# SAM9X75D1GN2 device description
Architecture: ARM926EJ-S; Family: SAM9; Series: SAM9X7
Registers are 32-bit, read-write, reset 0x0 unless marked. A register's access mark holds for its fields unless they carry their own. Offsets are from the block's base; [hi:lo] are bit positions; lines under a group give offsets from that group; {n}, {i} and the like mark numbered series.

## CSI2DC — CSI-2 Demultiplexer Controller
Instances: CSI2DC 0xF805C000
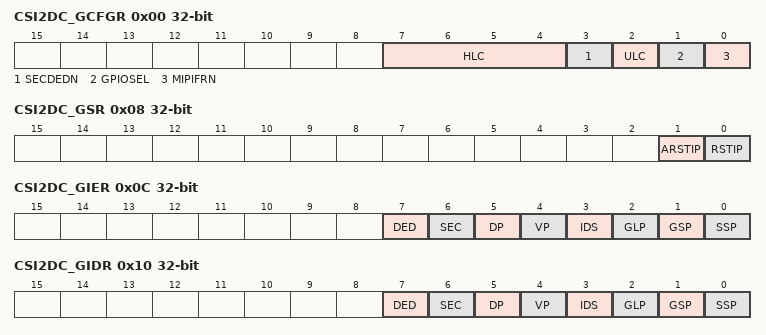
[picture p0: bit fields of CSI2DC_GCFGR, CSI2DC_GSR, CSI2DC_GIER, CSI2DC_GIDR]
0x00 CSI2DC_GCFGR — Global Configuration Register
  [7:4] HLC — CSI2DC Output Waveform Inter-line Minimum Delay
  [3] SECDEDN — Single Error Correction Double Error Detection Enable
    0=Packet header error correction is activated; 1=Packet header error correction is disabled
  [2] ULC — Use Optional Line Packet Delimiter
    0=Line packets are not used to define the line boundary; 1=Line Start and Line End optional packets are used to activate and deactivate the line
  [1] GPIOSEL — GPIO Parallel Interface Selection
    0=The MIPI CSI-2 serial interface is activated; 1=The GPIO parallel interface is selected and internally routed to the Image Signal Processor
  [0] MIPIFRN — MIPI Interface Free Running Clock
    0=The sensor MIPI clock is free-running; 1=The sensor MIPI clock is gated
0x04 CSI2DC_GCTLR wo reset not defined — Global Control Register
  [0] SWRST — Software Reset
    0=No effect; 1=Starts a software reset operation
0x08 CSI2DC_GSR ro — Global Status Register
  [1] ARSTIP — Asynchronous Reset in Progress
    0=No reset in progress for the asynchronous domain; 1=Asynchronous domain is being reset
  [0] RSTIP — Reset in Progress
    0=No reset in progress for the synchronous domain; 1=Synchronous domain is being reset
0x0C CSI2DC_GIER wo reset not defined (atomic set of CSI2DC_GIMR) — Global Interrupt Enable Register
  [7] DED — Packet Header Double Bit Error Detected Enable
  [6] SEC — Packet Header Single Bit Error Corrected Enable
  [5] DP — Data Pipe Interrupt Enable
  [4] VP — Video Pipe Interrupt Enable
  [3] IDS — Image Data Packet Snoop Controller Interrupt Enable
  [2] GLP — Generic Long Packet Interrupt Enable
  [1] GSP — Generic Short Packet Interrupt Enable
  [0] SSP — Synchronization Short Packet Interrupt Enable
0x10 CSI2DC_GIDR wo reset not defined (atomic clear of CSI2DC_GIMR) — Global Interrupt Disable Register
  [7] DED — Double Bit Error Detected Interrupt Disable
  [6] SEC — Single Bit Error Corrected Interrupt Disable
  [5] DP — Data Pipe Interrupt Disable
  [4] VP — Video Pipe Interrupt Disable
  [3] IDS — Image Data Packet Snoop Controller Interrupt Disable
  [2] GLP — Generic Long Packet Interrupt Disable
  [1] GSP — Generic Short Packet Interrupt Disable
  [0] SSP — Synchronization Short Packet Interrupt Disable
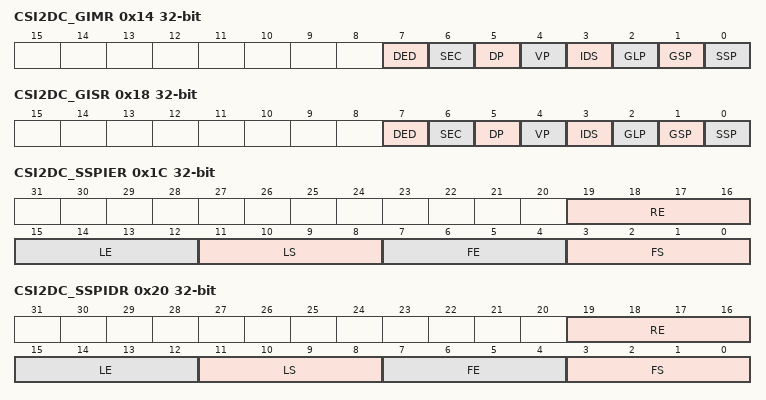
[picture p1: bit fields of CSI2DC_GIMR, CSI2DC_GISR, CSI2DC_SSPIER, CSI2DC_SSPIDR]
0x14 CSI2DC_GIMR ro — Global Interrupt Mask Register
  [7] DED — Double Error Detected Interrupt Disable Interrupt Mask
  [6] SEC — Single Error Corrected Interrupt Disable Interrupt Mask
  [5] DP — Data Pipe Interrupt Disable Interrupt Mask
  [4] VP — Video Pipe Interrupt Disable Interrupt Mask
  [3] IDS — Image Data Packet Snoop Controller Interrupt Mask
  [2] GLP — Generic Long Packet Interrupt Mask
  [1] GSP — Generic Short Packet Interrupt Mask
  [0] SSP — Synchronization Short Packet Interrupt Mask
0x18 CSI2DC_GISR ro — Global Interrupt Status Register
  [7] DED — Double Bit Error Detected Interrupt Status
    0=No double bit error detected is pending; 1=A double bit error has been detected in the packet header. This bit is reset after the register read operation.
  [6] SEC — Single Bit Error Corrected Interrupt Status
    0=No Single Bit Error Corrected interrupt is pending; 1=A single bit error has been detected and corrected in the packet header. This bit is reset after the register read operation.
  [5] DP — Data Pipe Interrupt Status
    0=Either the interrupt source is masked at the DP level or no interrupt is pending for DP; 1=A Data Pipe interrupt is pending
  [4] VP — Video Pipe Interrupt Status
    0=Either the interrupt source is masked at the VP level or no interrupt is pending for VP; 1=A Video Pipe interrupt is pending
  [3] IDS — Image Data Packet Snoop Controller Interrupt Status
    0=Either the interrupt source is masked at the IDS level or no interrupt is pending for IDS; 1=A new Image Data packet interrupt is pending
  [2] GLP — Generic Long Packet Interrupt Status
    0=Either the interrupt source is masked at the GLP level or no interrupt is pending for GLP; 1=A Generic Long packet interrupt is pending
  [1] GSP — Generic Short Packet Interrupt Status
    0=Either the interrupt source is masked at the GSP level or no interrupt is pending for GSP; 1=A Generic Short packet interrupt is pending
  [0] SSP — Synchronization Short Packet Interrupt Status
    0=Either the interrupt source is masked at the SSP level or no interrupt is pending for SSP; 1=A Synchronization Short packet interrupt is pending
0x1C CSI2DC_SSPIER wo reset not defined (atomic set of CSI2DC_SSPIMR) — SSP Interrupt Enable Register
  [19:16] RE — Reserved Short Packet Interrupt Enable
    0=No effect; 1=Setting a bit at position i in the RE field will set the interrupt mask bit for virtual channel i, and this virtual channel can generate an interrupt when a Reserved Short packet is detected
  [15:12] LE — Line End Interrupt Enable
    0=No effect; 1=Setting a bit at position i in the LE field will set the interrupt mask bit for virtual channel i, and this virtual channel can generate an interrupt when a Line End is detected. Line Synchronization packets are optional.
  [11:8] LS — Line Start Interrupt Enable
    0=No effect; 1=Setting a bit at position i in the LS field will set the interrupt mask bit for virtual channel i, and this virtual channel can generate an interrupt when a Line Start is detected. Line Synchronization packets are optional.
  [7:4] FE — Frame End Interrupt Enable
    0=No effect; 1=Setting a bit at position i in the FE field will set the interrupt mask bit for virtual channel i, and this virtual channel can generate an interrupt when a Frame End is detected
  [3:0] FS — Frame Start Interrupt Enable
    0=No effect; 1=Setting a bit at position i in the FS field will set the interrupt mask bit for virtual channel i, and this virtual channel can generate an interrupt when a Frame Start is detected
0x20 CSI2DC_SSPIDR wo reset not defined (atomic clear of CSI2DC_SSPIMR) — SSP Interrupt Disable Register
  [19:16] RE — Reserved Short Packet Interrupt Disable
  [15:12] LE — Line End Interrupt Disable
  [11:8] LS — Line Start Interrupt Disable
  [7:4] FE — Frame End Interrupt Disable
  [3:0] FS — Frame Start Interrupt Disable
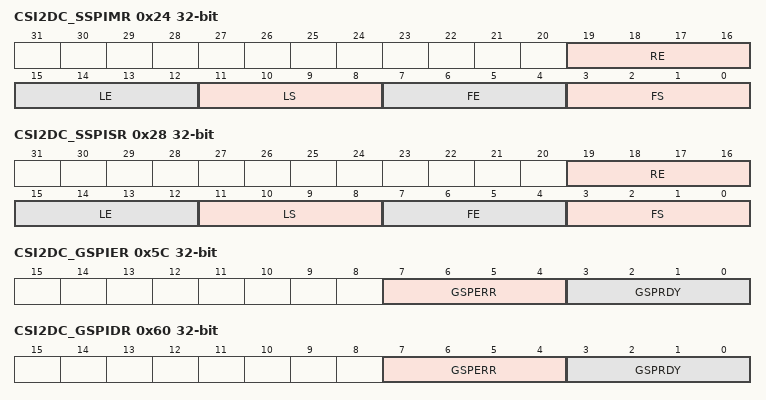
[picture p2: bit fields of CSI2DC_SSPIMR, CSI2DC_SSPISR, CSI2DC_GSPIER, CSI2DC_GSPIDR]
0x24 CSI2DC_SSPIMR ro — SSP Interrupt Mask Register
  [19:16] RE — Reserved Short Packet Interrupt Mask
    0=A bit cleared at position i in the field RE indicates that the Reserved packet interrupt is masked for virtual channel i; 1=A bit set at position i in field RE indicates that Reserved packet interrupt is activated for virtual channel i
  [15:12] LE — Line End Interrupt Mask
    0=A bit cleared at position i in the field LE indicates that the Line End interrupt is masked for virtual channel i; 1=A bit set at position i in field LE indicates that Line End interrupt is activated for virtual channel i
  [11:8] LS — Line Start Interrupt Mask
    0=A bit cleared at position i in the field LS indicates that the Line Start interrupt is masked for virtual channel i; 1=A bit set at position i in field LS indicates that Line Start interrupt is activated for virtual channel i
  [7:4] FE — Frame End Interrupt Mask
    0=A bit cleared at position i in the field FE indicates that the Frame End interrupt is masked for virtual channel i; 1=A bit set at position i in field FE indicates that Frame End interrupt is activated for virtual channel i
  [3:0] FS — Frame Start Interrupt Mask
    0=A bit cleared at position i in the field FS indicates that the Frame Start interrupt is masked for virtual channel i; 1=A bit set at position i in field FS indicates that Frame Start interrupt is activated for virtual channel i
0x28 CSI2DC_SSPISR ro — SSP Interrupt Status Register
  [19:16] RE — Reserved Short Packet Interrupt Status
    0=A bit cleared at position i in the field RE indicates that no Reserved Short packet interrupt is pending for virtual channel i; 1=A bit set at position i in the field RE indicates that no Reserved Short packet interrupt is pending for virtual channel i. This bit is reset after the register read operation.
  [15:12] LE — Line End Interrupt Status
    0=A bit cleared at position i in the field LE indicates that no Line End interrupt is pending for virtual channel i; 1=A bit set at position i in the field LE indicates that a Line End interrupt is pending for virtual channel i. This bit is reset after the register read operation.
  [11:8] LS — Line Start Interrupt Status
    0=A bit cleared at position i in the field LS indicates that no Line Start interrupt is pending for virtual channel i; 1=A bit set at position i in the field LS indicates that a Line Start interrupt is pending for virtual channel i. This bit is reset after the register read operation.
  [7:4] FE — Frame End Interrupt Status
    0=A bit cleared at position i in the field FE indicates that no Frame End interrupt is pending for virtual channel i; 1=A bit set at position i in the field FE indicates that a Frame End interrupt is pending for virtual channel i. This bit is reset after the register read operation..
  [3:0] FS — Frame Start Interrupt Status
    0=A bit cleared at position i in the field FS indicates that no Frame Start interrupt is pending for virtual channel i; 1=A bit set at position i in the field FS indicates that a Frame Start interrupt is pending for virtual channel i. This bit is reset after the register read operation.
{0x2C+4i} CSI2DC_FNVC{i}R ro (i=0..3) — Frame Number VC0 Register
  [15:0] FN — Frame Number for Virtual Channel 0
{0x3C+4i} CSI2DC_LNVC{i}R ro (i=0..3) — Line Number VC0 Register
  [15:0] LN — Line Number for Virtual Channel 0
0x5C CSI2DC_GSPIER wo reset not defined (atomic set of CSI2DC_GSPIMR) — GSP Interrupt Enable Register
  [7:4] GSPERR — Generic Short Packet Error Interrupt Enable
    0=No effect; 1=Setting a bit at position i in the GSPERR field will set the interrupt mask bit, and virtual channel i can generate a Generic Short Packet Error interrupt
  [3:0] GSPRDY — Generic Short Packet Ready Interrupt Enable
    0=No effect; 1=Setting a bit at position i in the GSPRDY field will set the interrupt mask bit, and virtual channel i can generate a Generic Short packet interrupt
0x60 CSI2DC_GSPIDR wo reset not defined (atomic clear of CSI2DC_GSPIMR) — GSP Interrupt Disable Register
  [7:4] GSPERR — Generic Short Packet Error Interrupt Disable
    0=No effect; 1=Setting a bit at position i in the GSPERR field will clear the interrupt mask bit for virtual channel i
  [3:0] GSPRDY — Generic Short Packet Ready Interrupt Disable
    0=No effect; 1=Setting a bit at position i in the GSPRDY field will clear the interrupt mask bit for virtual channel i
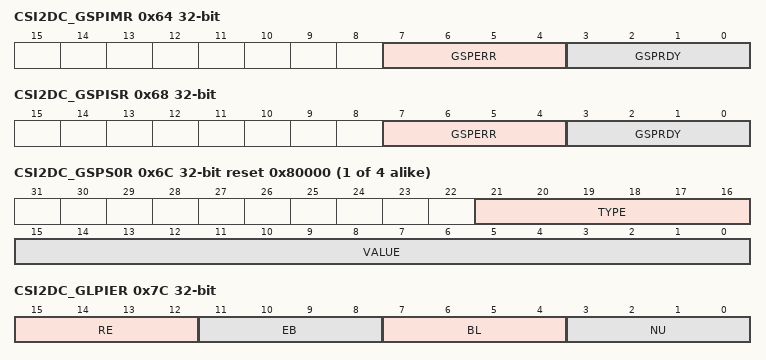
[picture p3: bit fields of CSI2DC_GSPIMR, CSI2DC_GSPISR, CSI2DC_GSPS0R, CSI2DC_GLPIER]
0x64 CSI2DC_GSPIMR ro — GSP Interrupt Mask Register
  [7:4] GSPERR — Generic Short Packet Error Interrupt Mask bit
    0=A bit cleared at position i in the field GSPERR indicates that the GSP Error interrupt is masked; 1=A bit set at position i in field GSPERR indicates that the GSP Error interrupt is activated
  [3:0] GSPRDY — Generic Short Packet Ready Interrupt Mask bit
    0=A bit cleared at position i in the field GSPRDY indicates that the GSP Ready interrupt is masked for virtual channel i; 1=A bit set at position i in field GSPRDY indicates that the GSP Ready interrupt is activated for virtual channel i
0x68 CSI2DC_GSPISR ro — GSP Interrupt Status Register
  [7:4] GSPERR — Generic Short Packet Error Interrupt Status Bit
    0=A bit cleared at position i in the field GSPERR indicates that no Generic Short Packet Error interrupt is pending for virtual channel i; 1=A bit set at position i in the field GSPERR indicates that a Generic Short Packet Error overflow interrupt has occurred since the last read of the status register. This bit is reset after the register read operation.
  [3:0] GSPRDY — Generic Short Packet Ready Interrupt Status Bit
    0=A bit cleared at position i in the field GSPRDY indicates that no Generic Short Packet Ready interrupt is pending for virtual channel i; 1=A bit set at position i in the field GSPRDY indicates that a Generic Short Packet Ready interrupt is pending for virtual channel i. This bit is reset after the register read operation.
{0x6C+4i} CSI2DC_GSPS{i}R ro reset 0x80000 (i=0..3) — GSP Status {i} Register
  [21:16] TYPE — Generic Short Packet Type Value for Virtual Channel 0
  [15:0] VALUE — Generic Short Packet 16-bit Data Value for Virtual Channel 0
0x7C CSI2DC_GLPIER wo reset not defined (atomic set of CSI2DC_GLPIMR) — GLP Interrupt Enable Register
  [15:12] RE — Reserved Packet Interrupt Enable Bit
    0=No effect; 1=Setting a bit at position i in the RE field sets the interrupt mask bit for virtual channel i, and this virtual channel can generate an interrupt when a reserved long packet is detected. A reserved long packet includes data types from 0x13 to 0x17.
  [11:8] EB — Embedded 8-bit Non-Image Data Interrupt Enable Bit
    0=No effect; 1=Setting a bit at position i in the EB field sets the interrupt mask bit for virtual channel i, and this virtual channel can generate an interrupt when a non-image data packet is detected
  [7:4] BL — Blanking Data Interrupt Enable Bit
    0=No effect; 1=Setting a bit at position i in the BL field sets the interrupt mask bit for virtual channel i, and this virtual channel can generate an interrupt when a Blank packet is detected
  [3:0] NU — Null Interrupt Enable Bit
    0=No effect; 1=Setting a bit at position i in the NU field sets the interrupt mask bit for virtual channel i, and this virtual channel can generate an interrupt when a null long packet is detected
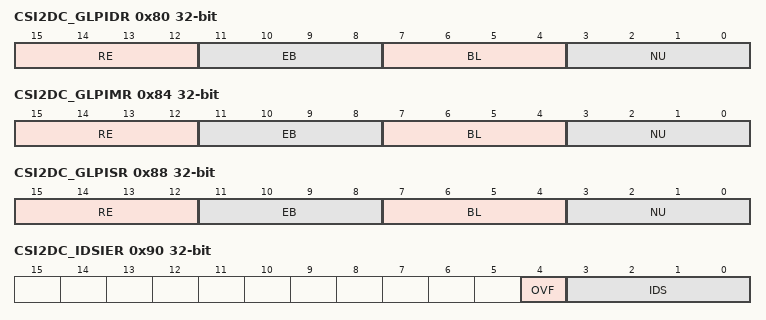
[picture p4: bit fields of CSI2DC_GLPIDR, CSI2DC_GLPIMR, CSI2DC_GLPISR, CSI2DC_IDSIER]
0x80 CSI2DC_GLPIDR wo reset not defined (atomic clear of CSI2DC_GLPIMR) — GLP Interrupt Disable Register
  [15:12] RE — Reserved Packet Interrupt Disable Bit
  [11:8] EB — Embedded 8-bit Non-Image Data Interrupt Disable Bit
  [7:4] BL — Blanking Data Interrupt Disable Bit
  [3:0] NU — Null Interrupt Disable Bit
0x84 CSI2DC_GLPIMR ro — GLP Interrupt Mask Register
  [15:12] RE — Reserved Packet Interrupt Mask Bit
    0=A bit cleared at position i in the field RE indicates that the Reserved Packet interrupt is masked for virtual channel i; 1=A bit set at position i in field NU indicates that the Reserved Packet interrupt is activated for virtual channel i
  [11:8] EB — Embedded 8-bit Non-Image Data Packet Interrupt Mask Bit
    0=A bit cleared at position i in the field EB indicates that the embedded data packet interrupt is masked for virtual channel i; 1=A bit set at position i in field EB indicates that the embedded data packet interrupt is activated for virtual channel i
  [7:4] BL — Blanking Data Packet Interrupt Mask Bit
    0=A bit cleared at position i in the field BL indicates that the Blanking Data Packet interrupt is masked for virtual channel i; 1=A bit set at position i in field BL indicates that the Blanking Data Packet interrupt is activated for virtual channel i
  [3:0] NU — Null Packet Interrupt Mask Bit
    0=A bit cleared at position i in the field NU indicates that the Null Packet interrupt is masked for virtual channel i; 1=A bit set at position i in field NU indicates that the Null Packet interrupt is activated for virtual channel i
0x88 CSI2DC_GLPISR ro — GLP Interrupt Status Register
  [15:12] RE — Reserved Generic Long Packet Ready Interrupt Status Bit
    0=A bit cleared at position i in the field BL indicates that no reserved packet interrupt is pending for virtual channel i; 1=A bit set at position i in the field BL indicates that a reserved packet interrupt is pending for virtual channel i. This bit is reset after the register read operation.
  [11:8] EB — Embedded 8-bit data Generic Long Packet Ready Interrupt Status Bit
    0=A bit cleared at position i in the field EB indicates that no embedded data packet interrupt is pending for virtual channel i; 1=A bit set at position i in the field EB indicates that an embedded data packet interrupt is pending for virtual channel i. This bit is reset after the register read operation.
  [7:4] BL — Blanking Data Generic Long Packet Ready Interrupt Status Bit
    0=A bit cleared at position i in the field BL indicates that no blanking data packet interrupt is pending for virtual channel i; 1=A bit set at position i in the field BL indicates that a blanking packet interrupt is pending for virtual channel i. This bit is reset after the register read operation.
  [3:0] NU — Null Generic Long Packet Ready Interrupt Status Bit
    0=A bit cleared at position i in the field NU indicates that no null packet interrupt is pending for virtual channel i; 1=A bit set at position i in the field NU indicates that a null packet interrupt is pending for virtual channel i. This bit is reset after the register read operation.
0x8C CSI2DC_IDSCR wo reset not defined — IDS Control Register
  [0] SWRST — Software Reset
    0=No effect; 1=Performs an IDS software reset of the table. Read value when set indicates that the software reset is in progress.
0x90 CSI2DC_IDSIER wo reset not defined (atomic set of CSI2DC_IDSIMR) — IDS Interrupt Enable Register
  [4] OVF — Image Data Snoop Overflow Interrupt Enable
    0=No effect; 1=Enables the Image Data Snoop Overflow interrupt
  [3:0] IDS — Image Data Snoop Interrupt Enable
    0=No effect; 1=Setting a bit at position i in the IDS field will set the interrupt mask bit for table entry i, and this entry can generate an interrupt when an image data packet is captured by the snoop controller
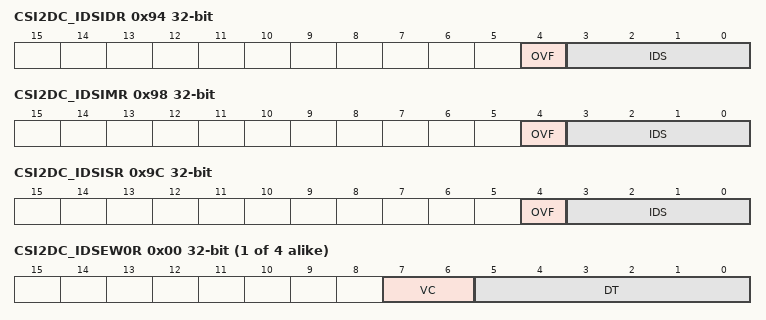
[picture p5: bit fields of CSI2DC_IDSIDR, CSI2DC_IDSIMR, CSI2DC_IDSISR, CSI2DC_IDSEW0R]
0x94 CSI2DC_IDSIDR wo reset not defined (atomic clear of CSI2DC_IDSIMR) — IDS Interrupt Disable Register
  [4] OVF — Image Data Snoop Overflow Interrupt Disable
    0=No effect; 1=Disables the Image Data Snoop Overflow interrupt
  [3:0] IDS — Image Data Snoop Interrupt Disable
    0=No effect; 1=Setting a bit at position i in the IDS field will clear the interrupt mask bit for table entry i
0x98 CSI2DC_IDSIMR ro — IDS Interrupt Mask Register
  [4] OVF — Image Data Snoop Overflow Interrupt Mask
    0=No effect; 1=Indicates that the Image Data Snoop Overflow interrupt is activated
  [3:0] IDS — Image Data Snoop Interrupt Mask Bit
    0=A bit cleared at position i in the field IDS indicates that the Image Data Snoop interrupt is masked for table entry i; 1=A bit set at position i in field IDS indicates that Image Data Snoop interrupt is activated for table entry i
0x9C CSI2DC_IDSISR ro — IDS Interrupt Status Register
  [4] OVF — Image Data Snoop Overflow Interrupt Status
    0=No effect; 1=Indicates that the IDS controller captured more than 4 entries. This bit is reset after the register read operation.
  [3:0] IDS — Image Data Snoop Interrupt Status Bit
    0=A bit cleared at position i in the field IDS indicates that no Image Data Snoop interrupt is pending for virtual channel i; 1=A bit set at position i in the field IDS indicates that a new Image Data Snoop entry interrupt is pending for table entry i. This bit is reset after the register read operation.
{0xA0+8i} CSI2DC_IDSEW[{i}] (i=0..3) group
  0x00 CSI2DC_IDSEW0R ro — IDS Entry Word 0 Register
    [7:6] VC — Virtual Channel Identifier
      {v}=Virtual Channel {v} (v=0..3)
    [5:0] DT — Data Type
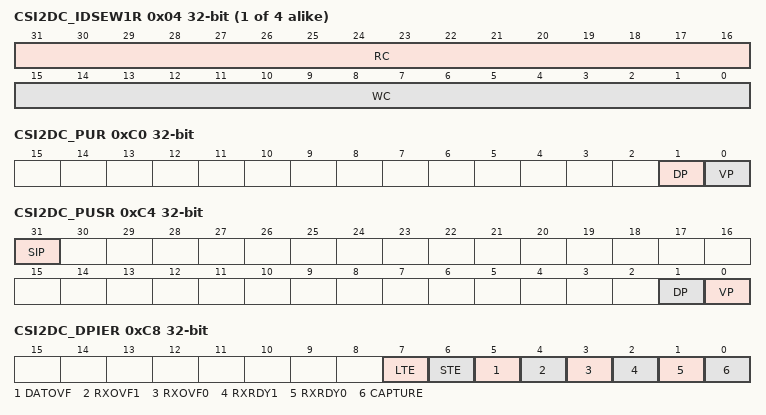
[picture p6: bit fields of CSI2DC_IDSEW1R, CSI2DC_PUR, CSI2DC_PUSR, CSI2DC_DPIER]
  0x04 CSI2DC_IDSEW1R ro — IDS Entry Word 1 Register
    [31:16] RC — Row Count for Image Data Packet Captured
    [15:0] WC — Word Count for Image Data Packet Captured
0xC0 CSI2DC_PUR wo reset not defined — Pipe Update Register
  [1] DP — Data Pipe Attributes Update
    0=No effect; 1=Transfers current configuration to Data Pipe Configuration registers on the next Frame Start packet detection if the FS packet virtual channel ID matches the CSI2DC_DPCFG.VC field. This field must be set after data pipe configuration, otherwise the settings will not be updated.
  [0] VP — Video Pipe Attributes Update
    0=No effect; 1=Transfers current configuration to Video Pipe Configuration registers on the next Frame Start packet detection if the FS packet virtual channel ID matches the CSI2DC_VPCFG.VC field. This field must be set after video pipe configuration, otherwise the settings will not be updated.
0xC4 CSI2DC_PUSR ro — Pipe Update Status Register
  [31] SIP — Synchronization In Progress
    0=No synchronization pending; 1=Synchronization across clock domain boundary is in progress. If the MIPI interface clock is gated, the synchronization procedure will wait for the first valid MIPI packet to activate the receiver clock.
  [1] DP — Data Pipe Update
    0=No data pipe in progress; 1=Data pipe configuration is in progress. This bit is cleared at the next Frame Start packet if the virtual channel identifier matches the CSI2DC_DPCFG.VC field.
  [0] VP — Video Pipe Update
    0=No video pipe in progress; 1=Video pipe configuration is in progress. This bit is cleared at the next Frame Start packet if the virtual channel identifier matches the CSI2DC_VPCFG.VC field.
0xC8 CSI2DC_DPIER wo reset not defined (atomic set of CSI2DC_DPIMR) — Data Pipe Interrupt Enable Register
  [7] LTE — Longer Than Expected Packet Received Interrupt Enable Bit
  [6] STE — Shorter Than Expected Packet Received Interrupt Enable
  [5] DATOVF — Data Pipe Overflow Interrupt Enable
  [4] RXOVF1 — Bank 1, Packet Overflow Interrupt Enable
  [3] RXOVF0 — Bank 0, Packet Overflow Interrupt Enable
  [2] RXRDY1 — Bank 1, Packet Received Interrupt Enable
  [1] RXRDY0 — Bank 0, Packet Received Interrupt Enable
  [0] CAPTURE — Data Pipe Capture Done Interrupt Enable
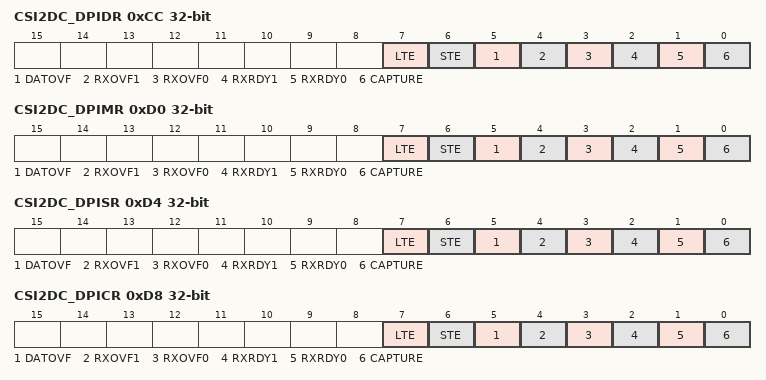
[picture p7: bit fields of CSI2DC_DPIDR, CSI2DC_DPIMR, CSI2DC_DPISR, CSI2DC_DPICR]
0xCC CSI2DC_DPIDR wo reset not defined (atomic clear of CSI2DC_DPIMR) — Data Pipe Interrupt Disable Register
  [7] LTE — Longer Than Expected Packet Received Interrupt Disable
  [6] STE — Shorter Than Expected Packet Received Interrupt Disable
  [5] DATOVF — Data Pipe Overflow Interrupt Disable
  [4] RXOVF1 — Bank 1, Packet Overflow Interrupt Disable
  [3] RXOVF0 — Bank 0, Packet Overflow Interrupt Disable
  [2] RXRDY1 — Bank 1, Packet Received Interrupt Disable
  [1] RXRDY0 — Bank 0, Packet Received Interrupt Disable
  [0] CAPTURE — Data Pipe Capture Done Interrupt Disable
0xD0 CSI2DC_DPIMR ro — Data Pipe Interrupt Mask Register
  [7] LTE — Longer Than Expected Packet Received Interrupt Mask
  [6] STE — Shorter Than Expected Packet Received Interrupt Mask
  [5] DATOVF — Data Pipe Overflow Interrupt Mask
  [4] RXOVF1 — Bank 1, Packet Overflow Interrupt Mask
  [3] RXOVF0 — Bank 0, Packet Overflow Interrupt Mask
  [2] RXRDY1 — Bank 1, Packet Received Interrupt Mask
  [1] RXRDY0 — Bank 0, Packet Received Interrupt Mask
  [0] CAPTURE — Data Pipe Capture Done Interrupt Mask
0xD4 CSI2DC_DPISR ro — Data Pipe Interrupt Status Register
  [7] LTE — Packet Longer Than Expected
    0=No LTE packet detected since the last clear operation of the register; 1=A packet has been received but the actual length is longer that the packet word count value
  [6] STE — Packet Shorter Than Expected
    0=No STE packet detected since the last clear operation of the register; 1=A packet has been received but the actual length is shorter that the packet word count value
  [5] DATOVF — Data Overflow
    0=No overflow detected since the last clear operation of the register; 1=Data overflow in the clock domain crossing FIFO
  [4] RXOVF1 — Bank 1 Overflow
    0=No overflow detected since the last clear operation of the register; 1=An overflow occurred in bank 1
  [3] RXOVF0 — Bank 0 Overflow
    0=No overflow detected since the last clear operation of the register; 1=An overflow occurred in bank 0
  [2] RXRDY1 — Bank 1 Packet Received
    0=No packet received in bank 1 since the last clear operation of the register; 1=A new packet has been captured in the data pipe
  [1] RXRDY0 — Bank 0 Packet Received
    0=No packet received in bank 0 since the last clear operation of the register; 1=A new packet has been captured in the data pipe
  [0] CAPTURE — Captured Frame
    0=No frame captured on the data pipe interface since the last clear operation of the register; 1=A new frame has been captured in the data pipe
0xD8 CSI2DC_DPICR wo reset not defined — Data Pipe Interrupt Clear Register
  [7] LTE — Packet Longer Than Expected Interrupt Clear Register
    0=No effect; 1=Clears the LTE interrupt
  [6] STE — Packet Shorter Than Expected Interrupt Clear Register
    0=No effect; 1=Clears the STE interrupt
  [5] DATOVF — Data Overflow Interrupt Clear Register
    0=No effect; 1=Clears the Data Overflow interrupt
  [4] RXOVF1 — Bank 1 Packet Overflow Interrupt Clear Register
    0=No effect; 1=Clears the Bank 1 Packet Overflow interrupt
  [3] RXOVF0 — Bank 0 Packet Overflow Interrupt Clear Register
    0=No effect; 1=Clears the Bank 0 Packet Overflow interrupt
  [2] RXRDY1 — Bank 1 Packet Received Interrupt Clear Register
    0=No effect; 1=Clears the Bank 1 Packet Received interrupt
  [1] RXRDY0 — Bank 0 Packet Received Interrupt Clear Register
    0=No effect; 1=Clears the Bank 0 Packet Received interrupt
  [0] CAPTURE — Captured Frame Interrupt Clear Register
    0=No effect; 1=Clears the Captured Frame interrupt
0xDC CSI2DC_DPER — Data Pipe Enable Register
  [0] ENABLE — Data Pipe Enable
    0=Data pipe disabled; 1=Data pipe enabled
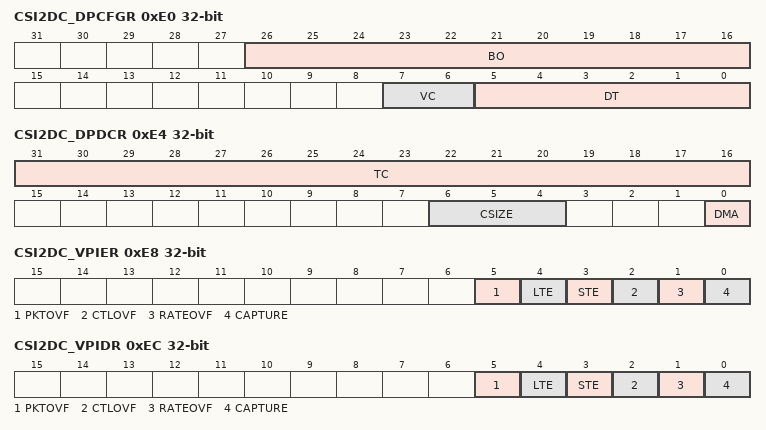
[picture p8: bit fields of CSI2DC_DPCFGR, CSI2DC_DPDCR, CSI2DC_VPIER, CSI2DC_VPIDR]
0xE0 CSI2DC_DPCFGR — Data Pipe Configuration Register
  [26:16] BO — Bank Offset
  [7:6] VC — Virtual Channel for Data Pipe
  [5:0] DT — Data Type for Data Pipe
0xE4 CSI2DC_DPDCR — Data Pipe DMA Configuration Register
  [31:16] TC — DMA Transfer Count
  [6:4] CSIZE — DMA Chunk Size
    0=CHK_1 (1 data transferred); 1=CHK_2 (2 data transferred); 2=CHK_4 (4 data transferred); 3=CHK_8 (8 data transferred); 4=CHK_16 (16 data transferred)
  [0] DMA — DMA Mode Enabled
    0=DMA client interface is disabled; 1=DMA client interface is enabled
0xE8 CSI2DC_VPIER wo reset not defined (atomic set of CSI2DC_VPIMR) — Video Pipe Interrupt Enable Register
  [5] PKTOVF — Packet Overflow For Video Pipe Interrupt Enable
  [4] LTE — Packet Longer Than Expected Interrupt Enable
  [3] STE — Packet Shorter Than Expected Interrupt Enable
  [2] CTLOVF — Control Buffer Overflow Interrupt Enable
  [1] RATEOVF — Rate Buffer Overflow Interrupt Enable
  [0] CAPTURE — Video Pipeline Capture Interrupt Enable
0xEC CSI2DC_VPIDR wo reset not defined (atomic clear of CSI2DC_VPIMR) — Video Pipe Interrupt Disable Register
  [5] PKTOVF — Packet Overflow For Video Pipe Interrupt Disable
  [4] LTE — Packet Longer Than Expected Interrupt Disable
  [3] STE — Packet Shorter Than Expected Interrupt Disable
  [2] CTLOVF — Control Buffer Overflow Interrupt Disable
  [1] RATEOVF — Rate Buffer Overflow Interrupt Disable
  [0] CAPTURE — Video Pipeline Capture Interrupt Disable
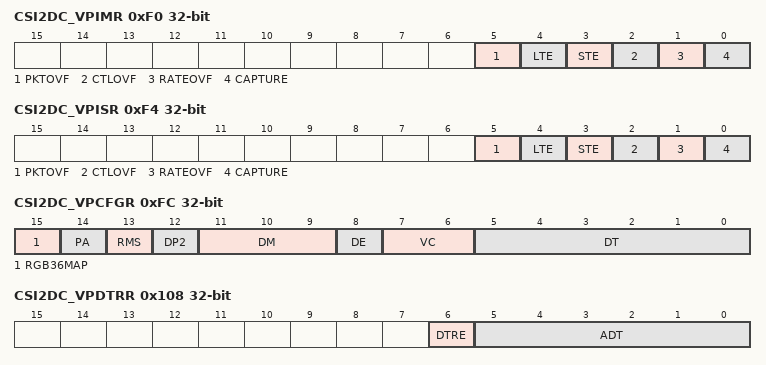
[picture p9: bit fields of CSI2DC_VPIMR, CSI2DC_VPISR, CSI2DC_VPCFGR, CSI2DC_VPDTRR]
0xF0 CSI2DC_VPIMR ro — Video Pipe Interrupt Mask Register
  [5] PKTOVF — Packet Overflow For Video Pipe Interrupt Mask
  [4] LTE — Packet Longer Than Expected Interrupt Mask
  [3] STE — Packet Shorter Than Expected Interrupt Mask
  [2] CTLOVF — Control Buffer Overflow Interrupt Mask
  [1] RATEOVF — Rate Buffer Overflow Interrupt Mask
  [0] CAPTURE — Video Pipeline Capture Interrupt Mask
0xF4 CSI2DC_VPISR ro — Video Pipe Interrupt Status Register
  [5] PKTOVF — Packet Overflow For Video Pipe Interrupt Status
    0=No packet overflow since the last read of the register; 1=A packet overflow has been detected
  [4] LTE — Packet Longer Than Expected Interrupt Status
    0=No packet longer than expected since the last read of the register; 1=A packet longer than expected has been detected
  [3] STE — Packet Shorter Than Expected Interrupt Status
    0=No packet shorter than expected since the last read of the register; 1=A packet shorter than expected has been detected
  [2] CTLOVF — Control Buffer Overflow Interrupt Status
    0=No Control Buffer Overflow since the last read of the register; 1=A Control Buffer Overflow has been detected
  [1] RATEOVF — Rate Buffer Overflow Interrupt Status
    0=No Rate Buffer Overflow since the last read of the register; 1=A Rate Buffer Overflow has been detected
  [0] CAPTURE — Video Pipeline Capture Status
    0=No frame capture since the last read of the register; 1=A frame has been captured in the video pipeline
0xF8 CSI2DC_VPER — Video Pipe Enable Register
  [0] ENABLE — Video Pipe Enable
    0=Video pipe disabled; 1=Video pipe enabled
0xFC CSI2DC_VPCFGR — Video Pipe Configuration Register
  [15] RGB36MAP — RGB Mapping
    0=RGB data is packed and written to the output bus; 1=The RGB pixel is mapped onto the 36-bit bus, using pixel expansion and replication
  [14] PA — ISC Post Adjustment
    0=Post adjustment is disabled. Video pipe output data are LSB aligned (left untouched).; 1=Post adjustment is enabled. Video pipe output data are MSB aligned according to 12-bit ISC data bus.
  [13] RMS — Recommended Memory Storage
    0=CSI2DC outputs 1 pixel per component per clock cycle, compliant with the ISC processing engine; 1=CSI2DC generates a byte stream compliant with the CSI-2 specification memory format
  [12] DP2 — Decoder Predictor 2 Selection
    0=Predictor 1 is selected; 1=Predictor 2 is selected
  [11:9] DM — Decoder Mode
    0=DECODER8TO12 (Use the 8-bit to 12-bit decoding operation); 1=DECODER7TO12 (Use the 7-bit to 12-bit decoding operation); 2=DECODER6TO12 (Use the 6-bit to 12-bit decoding operation); 3=DECODER8TO10 (Use the 8-bit to 10-bit decoding operation); 4=DECODER7TO10 (Use the 7-bit to 10-bit decoding operation); 5=DECODER6TO10 (Use the 6-bit to 10-bit decoding operation)
  [8] DE — Decompression Enable
    0=Decompression disabled; 1=Decompression enabled
  [7:6] VC — Virtual Channel Identifier
  [5:0] DT — Data Type
0x100 CSI2DC_VPCOLR ro — Video Pipe Column Register
  [15:0] COL — Column Number
0x104 CSI2DC_VPROWR ro — Video Pipe Row Register
  [15:0] ROW — Row Number
0x108 CSI2DC_VPDTRR wo — Video Pipe Data Type Remap Register
  [6] DTRE — Data Type Remap Enable
    0=Data type remap is disabled; 1=Data type remap is enabled
  [5:0] ADT — Alternate Data Type

## Notices in the file
Copyright (c) 2024 Microchip Technology Inc.
SPDX-License-Identifier: Apache-2.0
Licensed under the Apache License, Version 2.0 (the "License");
you may not use this file except in compliance with the License.
You may obtain a copy of the License at
http://www.apache.org/licenses/LICENSE-2.0
Unless required by applicable law or agreed to in writing, software
distributed under the License is distributed on an "AS IS" BASIS,
WITHOUT WARRANTIES OR CONDITIONS OF ANY KIND, either express or implied.
See the License for the specific language governing permissions and
limitations under the License.
